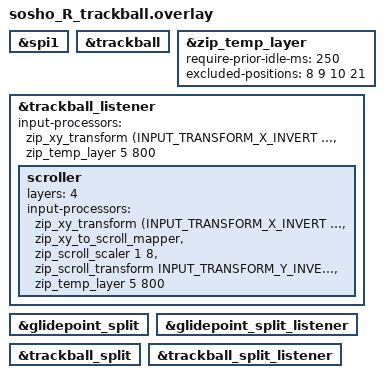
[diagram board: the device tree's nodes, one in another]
#include "sosho_R.dtsi"

/*
glidepoint_listnerは右手のトラックパッド
glidepoint_split_listenerとtrackball_split_listenerは
左手のトラックパッドとトラックボールの受けです。
ここにinput-processorというオプションをつけると、いろんな動きができます。
代表的なものを書いておきます。

・ポインタの移動を早くしたいとき
&zip_xy_scalerを使います。
分子 分母の順に数字を指定します。2 1なら2倍です。
input-processors = <&zip_xy_scaler 2 1>;

・スクロールを割り当てたいとき
zip_xy_to_scroll_mapperを使います。
ポインティングデバイスの動きをスクロールに変換してくれます。
input-processors = <&zip_xy_to_scroll_mapper>;

・移動を反転したいとき
zip_xy_transformを使います。
これは&trackball_listenerで実際に使っています。

これらオプションは複数併記することもできます。
input-processors = <&zip_xy_scaler 1 3>,<&zip_xy_to_scroll_mapper>;

詳しい情報はzmkのドキュメントを確認してください。
https://zmk.dev/docs/keymaps/input-processors
*/

&spi1 { status = "okay"; };
&trackball { status = "okay"; };
/*
オートマウスレイヤー
トラックボールを動かすとマウスレイヤー(レイヤー5)が有効になります。
・&zip_temp_layer 5 800 : 最後に動かしてから800msでレイヤー5を解除
・require-prior-idle-ms : 文字入力の直後この時間はボールが触れても有効にしない
・excluded-positions    : 押してもマウスレイヤーを解除しないキー (I O P L)
*/
&zip_temp_layer {
	require-prior-idle-ms = <250>;
	excluded-positions = <8 9 10 21>;
};

&trackball_listener {
	status = "okay";
	input-processors = <&zip_xy_transform (INPUT_TRANSFORM_X_INVERT | INPUT_TRANSFORM_Y_INVERT)>,
	                   <&zip_temp_layer 5 800>;

	/*
	スクロールモード (レイヤー4、マウスレイヤーでLを押している間)
	・&zip_scroll_scaler 1 8 : ボールの動き1/8をスクロール量に。速すぎる/遅すぎるときはここを調整
	・&zip_scroll_transform  : ボールを奥に転がすと上スクロール。逆にしたい場合はこの行を消す
	*/
	scroller {
		layers = <4>;
		input-processors = <&zip_xy_transform (INPUT_TRANSFORM_X_INVERT | INPUT_TRANSFORM_Y_INVERT)>,
		                   <&zip_xy_to_scroll_mapper>,
		                   <&zip_scroll_scaler 1 8>,
		                   <&zip_scroll_transform INPUT_TRANSFORM_Y_INVERT>,
		                   <&zip_temp_layer 5 800>;
	};
};

&glidepoint_split { status = "okay"; };
&glidepoint_split_listener {
    status = "okay";
	//input-processors = <&zip_xy_scaler 2 1>;
};

&trackball_split { status = "okay"; };
&trackball_split_listener {
	status = "okay"; 
	//input-processors = <&zip_xy_to_scroll_mapper>;
};
